# N572F065_v3 register map
File version: 1.0
Registers are 32-bit, read-write, reset 0x0 unless marked. A register's access mark holds for its fields unless they carry their own. Offsets are from the block's base; [hi:lo] are bit positions; lines under a group give offsets from that group; {n}, {i} and the like mark numbered series.

## USBD — USBD Register Map
Base 0x40060000
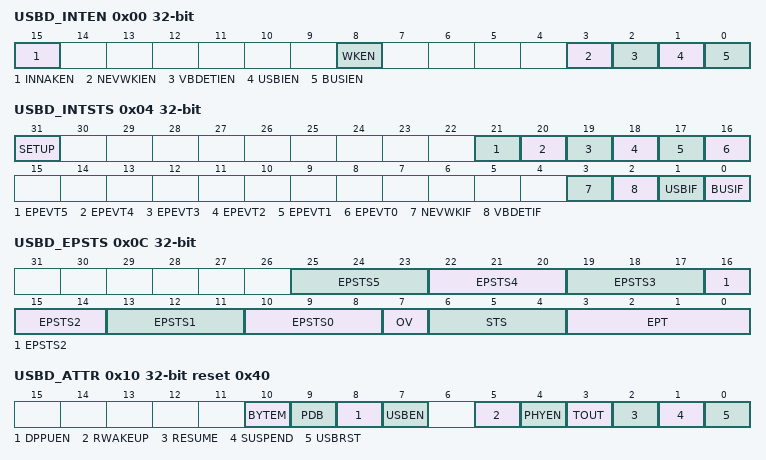
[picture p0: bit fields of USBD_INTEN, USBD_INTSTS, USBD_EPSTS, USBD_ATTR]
0x00 USBD_INTEN — USB Device Interrupt Enable Register
  [15] INNAKEN — Active NAK Function And Its Status In IN Token
    0=When device responds NAK after receiving IN token, IN NAK status will not be updated to USBD_EPSTS register, so that the USB interrupt event will not be asserted; 1=IN NAK status will be updated to USBD_EPSTS register and the USB interrupt event will be asserted, when the device responds NAK after receiving IN token
  [8] WKEN — Wake-Up Function Enable Bit
    0=USB wake-up function Disabled; 1=USB wake-up function Enabled
  [3] NEVWKIEN — USB No-Event-Wake-Up Interrupt Enable Bit
    0=No-event-wake-up Interrupt Disabled; 1=No-event-wake-up Interrupt Enabled
  [2] VBDETIEN — VBUS Detection Interrupt Enable Bit
    0=VBUS detection Interrupt Disabled; 1=VBUS detection Interrupt Enabled
  [1] USBIEN — USB Event Interrupt Enable Bit
    0=USB event interrupt Disabled; 1=USB event interrupt Enabled
  [0] BUSIEN — Bus Event Interrupt Enable Bit
    0=BUS event interrupt Disabled; 1=BUS event interrupt Enabled
0x04 USBD_INTSTS — USB Device Interrupt Event Status Register
  [31] SETUP — Setup Event Status
    0=No Setup event; 1=Setup event occurred, cleared by write 1 to USBD_INTSTS[31]
  [21] EPEVT5 — Endpoint 5's USB Event Status
    0=No event occurred in endpoint 5; 1=USB event occurred on Endpoint 5, check USBD_EPSTS[25:23] to know which kind of USB event was occurred, cleared by write 1 to USBD_INTSTS[21] or USBD_INTSTS[1]
  [20] EPEVT4 — Endpoint 4's USB Event Status
    0=No event occurred in endpoint 4; 1=USB event occurred on Endpoint 4, check USBD_EPSTS[22:20] to know which kind of USB event was occurred, cleared by write 1 to USBD_INTSTS[20] or USBD_INTSTS[1]
  [19] EPEVT3 — Endpoint 3's USB Event Status. USBD_INTSTS[1].
    0=No event occurred in endpoint 3; 1=USB event occurred on Endpoint 3, check USBD_EPSTS[19:17] to know which kind of USB event was occurred, cleared by write 1 to USBD_INTSTS[19] or
  [18] EPEVT2 — Endpoint 2's USB Event Status
    0=No event occurred in endpoint 2; 1=USB event occurred on Endpoint 2, check USBD_EPSTS[16:14] to know which kind of USB event was occurred, cleared by write 1 to USBD_INTSTS[18] or USBD_INTSTS[1]
  [17] EPEVT1 — Endpoint 1's USB Event Status
    0=No event occurred in endpoint 1; 1=USB event occurred on Endpoint 1, check USBD_EPSTS[13:11] to know which kind of USB event was occurred, cleared by write 1 to USBD_INTSTS[17] or USBD_INTSTS[1]
  [16] EPEVT0 — Endpoint 0's USB Event Status
    0=No event occurred in endpoint 0; 1=USB event occurred on Endpoint 0, check USBD_EPSTS[10:8] to know which kind of USB event was occurred, cleared by write 1 to USBD_INTSTS[16] or USBD_INTSTS[1]
  [3] NEVWKIF — No-Event-Wake-Up Interrupt Status
    0=NEVWK event does not occur; 1=No-event-wake-up event occurred, cleared by write 1 to USBD_INTSTS[3]
  [2] VBDETIF — VBUS Detection Interrupt Status
    0=There is not attached/detached event in the USB; 1=There is attached/detached event in the USB bus and it is cleared by write 1 to USBD_INTSTS[2]
  [1] USBIF — USB Event Interrupt Status. The USB event includes the SETUP Token, IN Token, OUT ACK, ISO IN, or ISO OUT events in the bus.
    0=No USB event occurred; 1=USB event occurred, check EPSTS0~5[2:0] to know which kind of USB event was occurred, cleared by write 1 to USBD_INTSTS[1] or EPSTS0~7 and SETUP (USBD_INTSTS[31])
  [0] BUSIF — BUS Interrupt Status. The BUS event means that there is one of the suspense or the resume function in the bus.
    0=No BUS event occurred; 1=Bus event occurred; check USBD_ATTR[3:0] to know which kind of bus event was occurred, cleared by write 1 to USBD_INTSTS[0]
0x08 USBD_FADDR — USB Device Function Address Register
  [6:0] FADDR — USB Device Function Address
0x0C USBD_EPSTS ro — USB Device Endpoint Status Register
  [3n+10:3n+8] EPSTS{n} (n=0..5) — Endpoint {n} Status. These bits are used to indicate the current status of this endpoint
    0=In ACK; 1=In NAK; 2=Out Packet Data0 ACK; 3=Setup ACK; 6=Out Packet Data1 ACK; 7=Isochronous transfer end
  [7] OV — Overrun. It indicates that the received data is over the maximum payload number or not.
    0=No overrun; 1=Out Data is more than the Max Payload in MXPLD register or the Setup Data is more than 8 Bytes
  [6:4] STS
    0=In ACK; 1=In NAK; 2=Out 0 ACK; 3=Setup ACK; 6=Out 1 ACK; 7=Isochronous translation end
  [3:0] EPT — Endpoint number
0x10 USBD_ATTR reset 0x40 — USB Device Bus Status and Attribution Register
  [10] BYTEM — CPU Access USB SRAM Size Mode Selection
    0=Word mode: The size of the transfer from CPU to USB SRAM can be Word only; 1=Byte mode: The size of the transfer from CPU to USB SRAM can be Byte only
  [9] PDB — Power Down USB-IP Related Power and Control
    0=Enable power down; 1=Disable power down
  [8] DPPUEN — Pull-Up Resistor On USB_DP Enable Bit
    0=Pull-up resistor in USB_D+ bus Disabled; 1=Pull-up resistor in USB_D+ bus Active
  [7] USBEN — USB Controller Enable Bit
    0=USB Controller Disabled; 1=USB Controller Enabled
  [5] RWAKEUP — Remote Wake-Up
    0=Release the USB bus from K state; 1=Force USB bus to K (USB_D+ low, USB_D-: high) state, used for remote wake-up
  [4] PHYEN — PHY Transceiver Function Enable Bit
    0=PHY transceiver function Disabled. The PHY means USB transceiver output; 1=PHY transceiver function Enabled
  [3] TOUT — Time-Out Status. Note: This bit is read only.
    0=No time-out; 1=No Bus response more than 18 bits time
  [2] RESUME — Resume Status. Note: This bit is read only.
    0=No bus resume; 1=Resume from suspend
  [1] SUSPEND — Suspend Status. Note: This bit is read only.
    0=Bus no suspend; 1=Bus idle more than 3ms, either cable is plugged off or host is sleeping
  [0] USBRST — USB Reset Status. Note: This bit is read only.
    0=Bus no reset; 1=Bus reset when SE0 (single-ended 0) more than 2.5us
0x14 USBD_VBUSDET ro — USB Device VBUS Detection Register
  [0] VBUSDET — Device VBUS Detection. Note: This bit is read only.
    0=Controller is not attached to the USB host; 1=Controller is attached to the USB host
0x18 USBD_STBUFSEG — SETUP Token Buffer Segmentation Register
  [8:3] STBUFSEG — SETUP Token Buffer Segmentation. It is used to indicate the offset address for the SETUP token with the USB Device SRAM starting address The effective starting address is. USBD_SRAM address + {STBUFSEG[8:3], 3'b000} Note: It is used for SETUP token only.
{0x20+0x10*i} USBD_BUFSEG{i} (i=0..5) — Endpoint 0 Buffer Segmentation Register
  [8:3] BUFSEG — Endpoint Buffer Segmentation. It is used to indicate the offset address for each endpoint with the USB SRAM starting address The effective starting address of the endpoint is. USBD_SRAM address + { BUFSEG[8:3], 3'b000} Refer to the section 5.5.4.7 for the endpoint SRAM structure and its description.
{0x24+0x10*i} USBD_MXPLD{i} (i=0..5) — Endpoint 0 Maximal Payload Register
  [8:0] MXPLD — Maximal Payload. Define the data length which is transmitted to host (IN token) or the actual data length which is received from the host (OUT token). It also used to indicate that the endpoint is ready to be transmitted in IN token or received in OUT token. (1) When the register is written by CPU, For IN token, the value of MXPLD is used to define the data length to be transmitted and indicate the data buffer is ready. For OUT token, it means that the controller is ready to receive data from the host and the value of MXPLD is the maximal data length comes from host. (2) When the register is read by CPU, For IN token, the value of MXPLD is indicated by the data length be transmitted to host. For OUT token, the value of MXPLD is indicated the actual data length receiving from host. Note: Once MXPLD is written, the data packets will be transmitted/received immediately after IN/OUT token arrived.
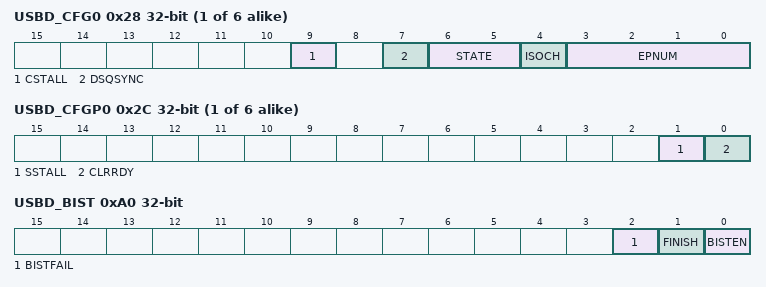
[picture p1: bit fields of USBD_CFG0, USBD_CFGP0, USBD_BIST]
{0x28+0x10*i} USBD_CFG{i} (i=0..5) — Endpoint 0 Configuration Register
  [9] CSTALL — Clear STALL Response
    0=Disable the device to clear the STALL handshake in setup stage; 1=Clear the device to response STALL handshake in setup stage
  [7] DSQSYNC — Data Sequence Synchronization. Note: It is used to specify the DATA0 or DATA1 PID in the following IN token transaction. hardware will toggle automatically in IN token base on the bit.
    0=DATA0 PID; 1=DATA1 PID
  [6:5] STATE — Endpoint STATE
    0=Endpoint is Disabled; 1=Out endpoint; 2=IN endpoint; 3=Undefined
  [4] ISOCH — Isochronous Endpoint. This bit is used to set the endpoint as Isochronous endpoint, no handshake.
    0=No Isochronous endpoint; 1=Isochronous endpoint
  [3:0] EPNUM — Endpoint Number. These bits are used to define the endpoint number of the current endpoint
{0x2C+0x10*i} USBD_CFGP{i} (i=0..5) — Endpoint 0 Set Stall and Clear In/Out Ready Control Register
  [1] SSTALL — Set STALL
    0=Disable the device to response STALL; 1=Set the device to respond STALL automatically
  [0] CLRRDY — Clear Ready. When the USBD_MXPLDx register is set by user, it means that the endpoint is ready to transmit or receive data. If the user wants to disable this transaction before the transaction start, users can set this bit to 1 to disable it and it is auto clear to 0. For IN token, write '1' to clear the IN token had ready to transmit the data to USB. For OUT token, write '1' to clear the OUT token had ready to receive the data from USB. This bit is written only and is always 0 when it is read back.
0x90 USBD_SE0 reset 0x1 — USB Device Drive SE0 Control Register
  [0] SE0 — Drive Single Ended Zero In USB Bus. The Single Ended Zero (SE0) is when both lines (USB_D+ and USB_D-) are being pulled low.
    0=Normal operation; 1=Force USB PHY transceiver to drive SE0
0xA0 USBD_BIST — USB Buffer Self-test Register
  [2] BISTFAIL — BIST Fail. The BISTFAIL indicates if the BIST test fails or succeeds. If the BISTFAIL is low at the end, the embedded SRAM pass the BIST test, otherwise, it is faulty. The BISTFAIL will be high once the BIST detects the error and remains high during the BIST operation. The BISTFAIL is a write clear field. Write 1 to this field clears the content and write 0 has no effect. Note: This bit is read only.
  [1] FINISH — BIST Operation Finish. It indicates the end of the BIST operation. When BIST controller finishes all operations, this bit will be set high. This bit is a write clear field. Write 1 to this field clears the content and write 0 has no effect. Note: This bit is read only.
  [0] BISTEN — BIST mode enable
    0=BIST is disabled or completed (automatically cleared by BIST controller); 1=BIST is enabled; begin to perform BIST on selected memory group
